# R7FA6M3AH register map
Vendor: Renesas; Series: RA6; File version: 1.2
CPU: CM4 r0p1, little endian, MPU, FPU, VTOR, 4 interrupt priority bits
Registers are 32-bit, read-write, reset 0x0 unless marked. A register's access mark holds for its fields unless they carry their own. Offsets are from the block's base; [hi:lo] are bit positions; {n}, {i} and the like mark numbered series.

## GPT_ODC — PWM Delay Generation Circuit
Base 0x4007B000
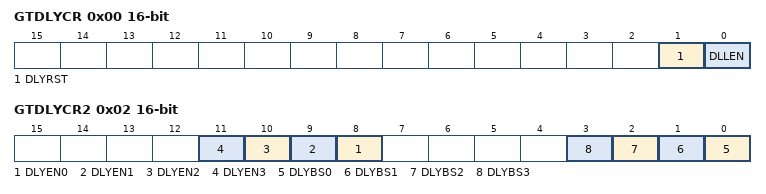
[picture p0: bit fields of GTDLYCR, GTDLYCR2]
0x00 GTDLYCR 16-bit — PWM Output Delay Control Register
  [1] DLYRST — PWM Delay Generation Circuit Reset
  [0] DLLEN — DLL Operation Enable
0x02 GTDLYCR2 16-bit — PWM Output Delay Control Register2
  [n+8] DLYEN{n} (n=0..3) — PWM Delay Generation Circuit enable for channel {n}
  [n] DLYBS{n} (n=0..3) — PWM Delay Generation Circuit bypass for channel {n}
{0x18+4i} GTDLYR{i}A (i=0..3) 16-bit (alternate view of GTDLYR{i}) — GTIOC{i}A Rising Output Delay Register
  [4:0] DLY — GTIOCnA Output Rising Edge Delay Setting
{0x1A+4i} GTDLYR{i}B (i=0..3) 16-bit (alternate view of GTDLYR{i}) — GTIOC{i}B Rising Output Delay Register
  [4:0] DLY — GTIOCnB Output Rising Edge Delay Setting
{0x28+4i} GTDLYF{i}A (i=0..3) 16-bit (alternate view of GTDLYF{i}) — GTIOC{i}A Falling Output Delay Register
  [4:0] DLY — GTIOCnA Output Falling Edge Delay Setting
{0x2A+4i} GTDLYF{i}B (i=0..3) 16-bit (alternate view of GTDLYF{i}) — GTIOC{i}B Falling Output Delay Register
  [4:0] DLY — GTIOCnB Output Falling Edge Delay Setting

## AGT0 — Asynchronous General purpose Timer 0
Base 0x40084000
Same registers: AGT1 0x40084100
0x00 AGT 16-bit reset 0xFFFF — AGT Counter Register
  [15:0] AGT — 16bit counter and reload registerNOTE : When 1 is written to the TSTOP bit in the AGTCRn register, the 16-bit counter is forcibly stopped and set to FFFFH.
0x02 AGTCMA 16-bit reset 0xFFFF — AGT Compare Match A Register
  [15:0] AGTCMA — AGT Compare Match A RegisterNOTE : When 1 is written to the TSTOP bit in the AGTCRn register, set to FFFFH
0x04 AGTCMB 16-bit reset 0xFFFF — AGT Compare Match B Register
  [15:0] AGTCMB — AGT Compare Match B RegisterNOTE : When 1 is written to the TSTOP bit in the AGTCR register, set to FFFFH
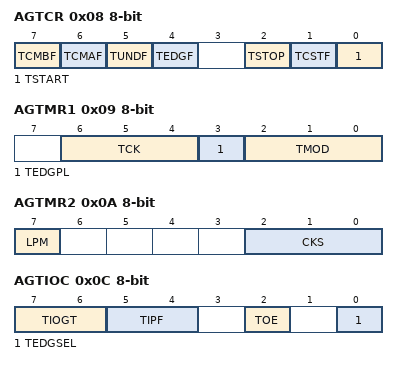
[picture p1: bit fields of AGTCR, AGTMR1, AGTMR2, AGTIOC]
0x08 AGTCR 8-bit — AGT Control Register
  [7] TCMBF write-0-clears read-modifies — AGT compare match B flag
  [6] TCMAF write-0-clears read-modifies — AGT compare match A flag
  [5] TUNDF write-0-clears read-modifies — AGT underflow flag
  [4] TEDGF write-0-clears read-modifies — Active edge judgement flag
  [2] TSTOP wo — AGT count forced stop
  [1] TCSTF ro — AGT count status flag
  [0] TSTART — AGT count start
0x09 AGTMR1 8-bit — AGT Mode Register 1
  [6:4] TCK — AGT count source select
  [3] TEDGPL — AGTIO edge polarity select
  [2:0] TMOD — AGT operating mode select
0x0A AGTMR2 8-bit — AGT Mode Register 2
  [7] LPM — AGT Low Power Mode
  [2:0] CKS — fsub/LOCO count source clock frequency division ratio select
0x0C AGTIOC 8-bit — AGT I/O Control Register
  [7:6] TIOGT — AGTIO count control
  [5:4] TIPF — AGTIO input filter select
  [2] TOE — AGTO output enable
  [0] TEDGSEL — I/O polarity switchFunction varies depending on the operating mode.
0x0D AGTISR 8-bit — AGT Event Pin Select Register
  [2] EEPS — AGTEE polarty selection
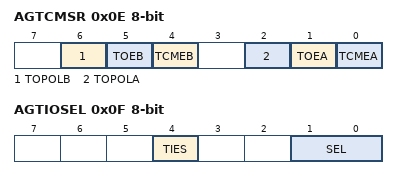
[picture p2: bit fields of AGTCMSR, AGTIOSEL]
0x0E AGTCMSR 8-bit — AGT Compare Match Function Select Register
  [6] TOPOLB — AGTOB polarity select
  [5] TOEB — AGTOB output enable
  [4] TCMEB — Compare match B register enable
  [2] TOPOLA — AGTOA polarity select
  [1] TOEA — AGTOA output enable
  [0] TCMEA — Compare match A register enable
0x0F AGTIOSEL 8-bit — AGT Pin Select Register
  [4] TIES — AGTIO input enable
  [1:0] SEL — AGTIO pin select

## FCACHE — Flash Cache
Base 0x4001C000
0x100 FCACHEE 16-bit — Flash Cache Enable Register
  [0] FCACHEEN — FCACHE Enable
0x104 FCACHEIV 16-bit — Flash Cache Invalidate Register
  [0] FCACHEIV write-1-sets read-modifies — FCACHE Invalidation
0x11C FLWT 8-bit — Flash Wait Cycle Register
  [2:0] FLWT — Flash Wait Cycle

## DAC12 — 12-bit D/A converter
Base 0x4005E000
{0x0+2i} DADR{i} (i=0..1) 16-bit — D/A Data Register {i}
  [15:0] DADR — D/A Data RegisterNOTE: When DADPR.DPSEL = 0, the high,order 4 bits are fixed to 0: right justified format. When DADPR.DPSEL = 1, the low,order 4 bits are fixed to 0: left justified format.
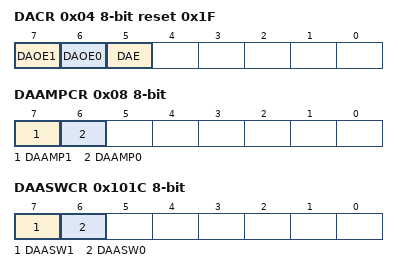
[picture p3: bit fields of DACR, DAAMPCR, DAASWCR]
0x04 DACR 8-bit reset 0x1F — D/A Control Register
  [7] DAOE1 — D/A Output Enable 1
  [6] DAOE0 — D/A Output Enable 0
  [5] DAE — D/A Enable
0x05 DADPR 8-bit — DADRm Format Select Register
  [7] DPSEL — DADRm Format Select
0x06 DAADSCR 8-bit — D/A,A/D Synchronous Start Control Register
  [7] DAADST — D/A,A/D Synchronous Conversion
0x08 DAAMPCR 8-bit — D/A Output Amplifier Control Register
  [7] DAAMP1 — Amplifier Control 1
  [6] DAAMP0 — Amplifier Control 0
0x101C DAASWCR 8-bit — D/A Amplifier Stabilization Wait Control Register
  [7] DAASW1 — D/A Amplifier Stabilization Wait 1
  [6] DAASW0 — D/A Amplifier Stabilization Wait 0
